# STM32F103 register map
File version: 1.0
CPU: CM3 r1p1, little endian, 4 interrupt priority bits
Registers are 32-bit, read-write, reset 0x0 unless marked. A register's access mark holds for its fields unless they carry their own. Offsets are from the block's base; [hi:lo] are bit positions; {n}, {i} and the like mark numbered series.

## CAN1 — Controller area network
Base 0x40006400
Same registers: CAN2 0x40006800
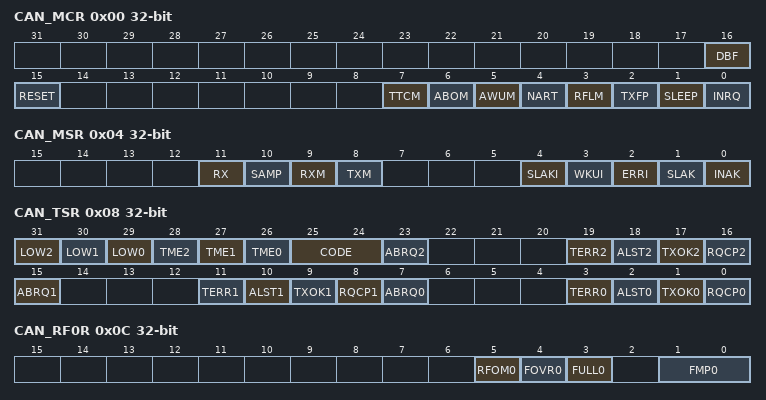
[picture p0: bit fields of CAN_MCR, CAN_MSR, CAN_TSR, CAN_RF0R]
0x00 CAN_MCR
  [16] DBF, [15] RESET, [7] TTCM, [6] ABOM, [5] AWUM, [4] NART, [3] RFLM, [2] TXFP, [1] SLEEP, [0] INRQ
0x04 CAN_MSR access per field
  [11] RX ro, [10] SAMP ro, [9] RXM ro, [8] TXM ro, [4] SLAKI rw, [3] WKUI rw, [2] ERRI rw, [1] SLAK ro, [0] INAK ro
0x08 CAN_TSR access per field
  [31] LOW2 ro — Lowest priority flag for mailbox 2
  [30] LOW1 ro — Lowest priority flag for mailbox 1
  [29] LOW0 ro — Lowest priority flag for mailbox 0
  [28] TME2 ro — Lowest priority flag for mailbox 2
  [27] TME1 ro — Lowest priority flag for mailbox 1
  [26] TME0 ro — Lowest priority flag for mailbox 0
  [25:24] CODE ro
  [23] ABRQ2 rw
  [19] TERR2 rw
  [18] ALST2 rw
  [17] TXOK2 rw
  [16] RQCP2 rw
  [15] ABRQ1 rw
  [11] TERR1 rw
  [10] ALST1 rw
  [9] TXOK1 rw
  [8] RQCP1 rw
  [7] ABRQ0 rw
  [3] TERR0 rw
  [2] ALST0 rw
  [1] TXOK0 rw
  [0] RQCP0 rw
0x0C CAN_RF0R access per field
  [5] RFOM0 rw, [4] FOVR0 rw, [3] FULL0 rw, [1:0] FMP0 ro
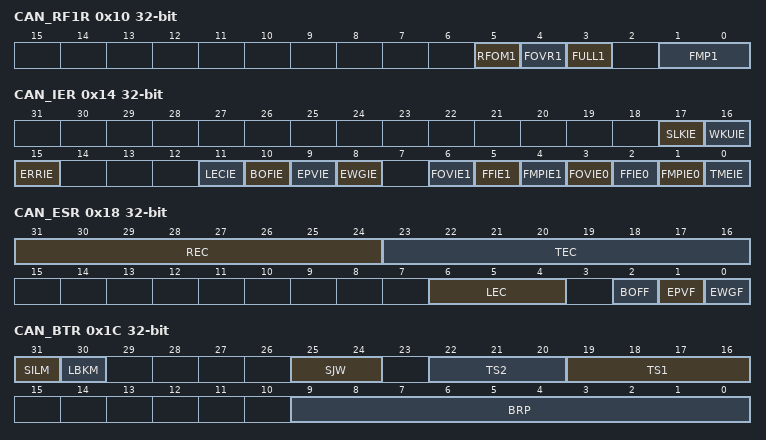
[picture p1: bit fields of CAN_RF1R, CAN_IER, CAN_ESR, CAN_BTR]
0x10 CAN_RF1R access per field
  [5] RFOM1 rw, [4] FOVR1 rw, [3] FULL1 rw, [1:0] FMP1 ro
0x14 CAN_IER
  [17] SLKIE, [16] WKUIE, [15] ERRIE, [11] LECIE, [10] BOFIE, [9] EPVIE, [8] EWGIE, [6] FOVIE1, [5] FFIE1, [4] FMPIE1, [3] FOVIE0, [2] FFIE0, [1] FMPIE0, [0] TMEIE
0x18 CAN_ESR access per field
  [31:24] REC ro, [23:16] TEC ro, [6:4] LEC rw, [2] BOFF ro, [1] EPVF ro, [0] EWGF ro
0x1C CAN_BTR
  [31] SILM, [30] LBKM, [25:24] SJW, [22:20] TS2, [19:16] TS1, [9:0] BRP
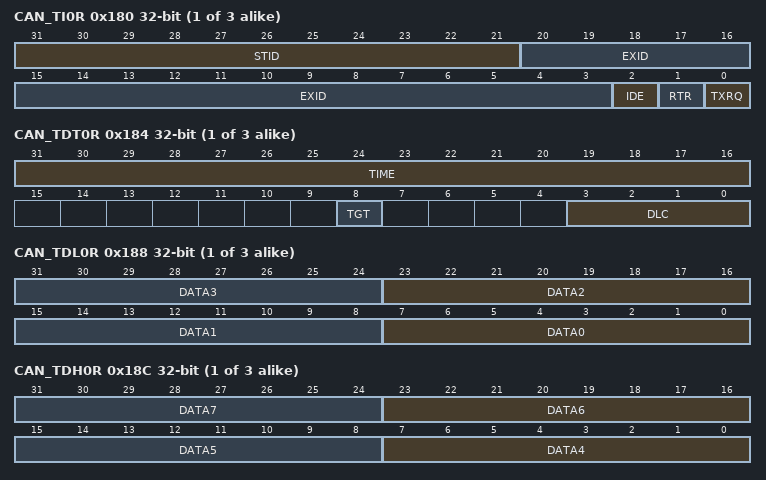
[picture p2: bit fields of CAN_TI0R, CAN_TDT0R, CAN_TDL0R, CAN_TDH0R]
{0x180+0x10*i} CAN_TI{i}R (i=0..2)
  [31:21] STID, [20:3] EXID, [2] IDE, [1] RTR, [0] TXRQ
{0x184+0x10*i} CAN_TDT{i}R (i=0..2)
  [31:16] TIME, [8] TGT, [3:0] DLC
{0x188+0x10*i} CAN_TDL{i}R (i=0..2)
  [8n+7:8n] DATA{n} (n=0..3)
{0x18C+0x10*i} CAN_TDH{i}R (i=0..2)
  [8n-25:8n-32] DATA{n} (n=4..7)
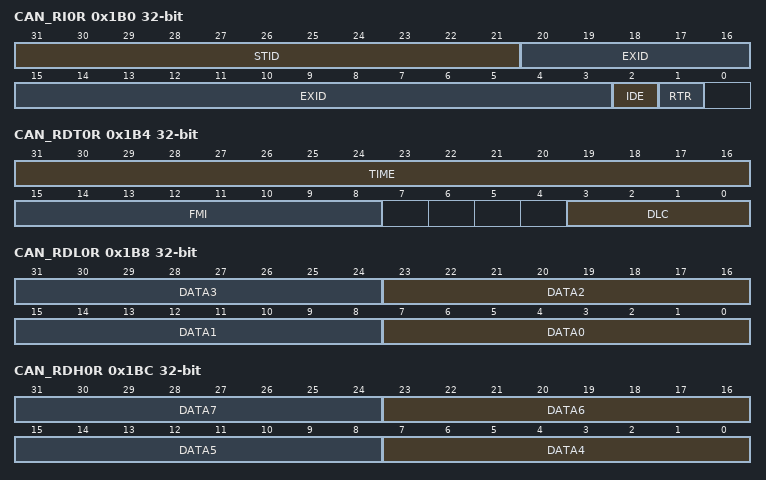
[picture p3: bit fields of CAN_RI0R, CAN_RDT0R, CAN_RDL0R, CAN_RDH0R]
0x1B0 CAN_RI0R ro
  [31:21] STID, [20:3] EXID, [2] IDE, [1] RTR
0x1B4 CAN_RDT0R ro
  [31:16] TIME, [15:8] FMI, [3:0] DLC
0x1B8 CAN_RDL0R ro
  [8n+7:8n] DATA{n} (n=0..3)
0x1BC CAN_RDH0R ro
  [8n-25:8n-32] DATA{n} (n=4..7)
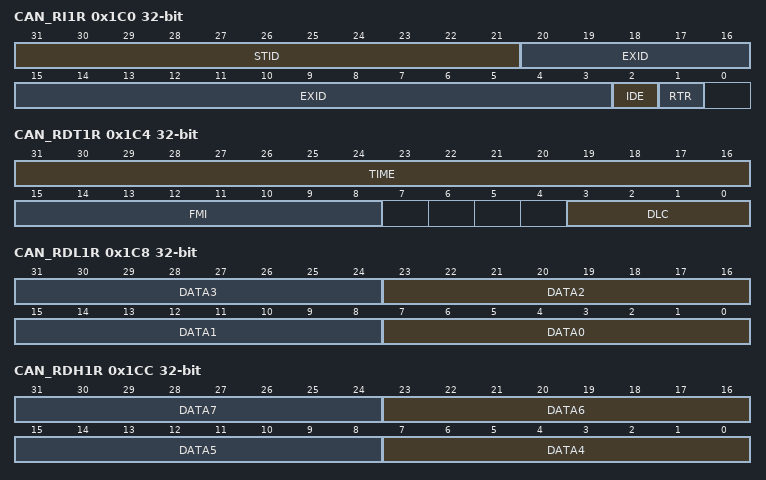
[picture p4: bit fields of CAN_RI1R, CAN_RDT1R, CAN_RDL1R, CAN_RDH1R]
0x1C0 CAN_RI1R ro
  [31:21] STID, [20:3] EXID, [2] IDE, [1] RTR
0x1C4 CAN_RDT1R ro
  [31:16] TIME, [15:8] FMI, [3:0] DLC
0x1C8 CAN_RDL1R ro
  [8n+7:8n] DATA{n} (n=0..3)
0x1CC CAN_RDH1R ro
  [8n-25:8n-32] DATA{n} (n=4..7)
0x200 CAN_FMR
  [0] FINIT
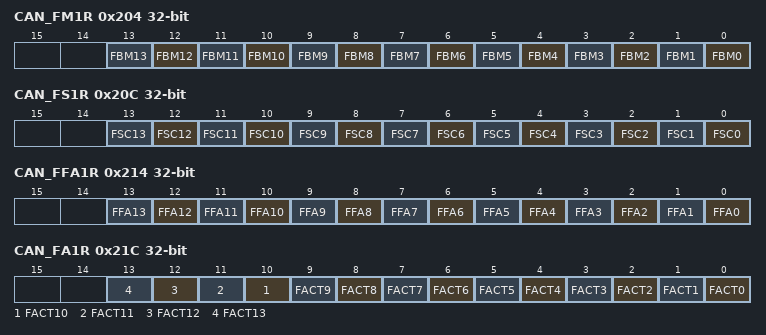
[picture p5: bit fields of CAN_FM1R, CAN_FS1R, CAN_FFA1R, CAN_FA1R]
0x204 CAN_FM1R
  [n] FBM{n} (n=0..13) — Filter mode
0x20C CAN_FS1R
  [n] FSC{n} (n=0..13) — Filter scale configuration
0x214 CAN_FFA1R
  [n] FFA{n} (n=0..13) — Filter FIFO assignment for filter {n}
0x21C CAN_FA1R
  [n] FACT{n} (n=0..13) — Filter active
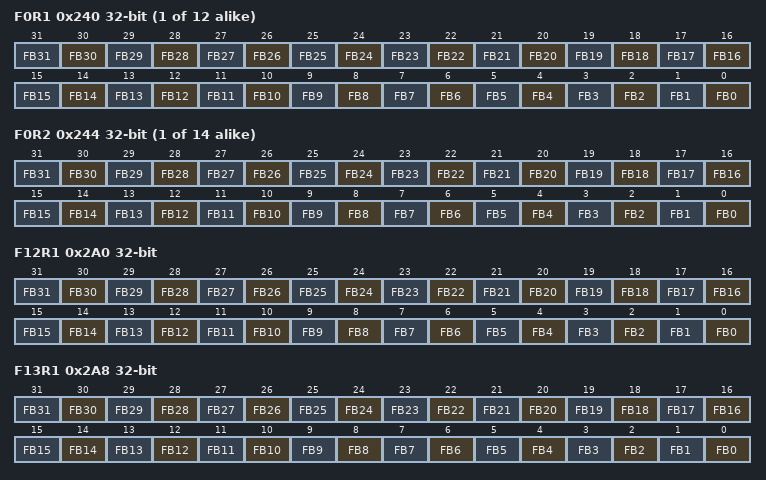
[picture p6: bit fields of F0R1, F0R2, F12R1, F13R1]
{0x240+8i} F{i}R1 (i=0..11) — Filter bank {i} register 1
  [n] FB{n} (n=0..31) — Filter bits
{0x244+8i} F{i}R2 (i=0..13) — Filter bank {i} register 2
  [n] FB{n} (n=0..31) — Filter bits
0x2A0 F12R1 — Filter bank 4 register 1
  [n] FB{n} (n=0..31) — Filter bits
0x2A8 F13R1 — Filter bank 13 register 1
  [n] FB{n} (n=0..31) — Filter bits

## DAC — Digital to analog converter
Base 0x40007400
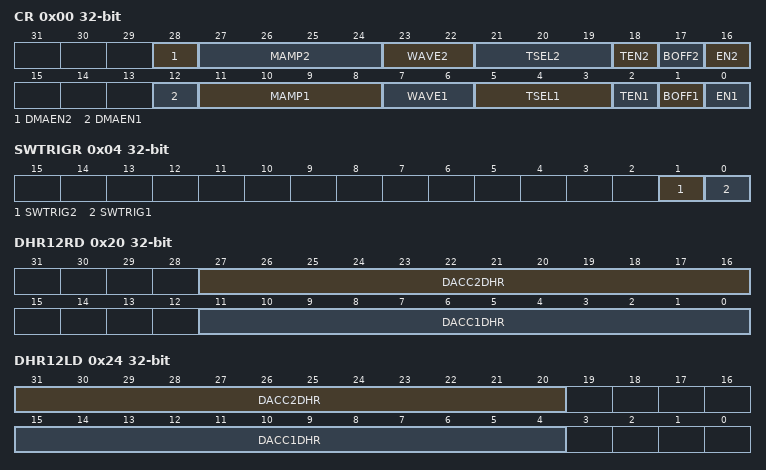
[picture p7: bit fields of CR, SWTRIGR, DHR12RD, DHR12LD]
0x00 CR — Control register (DAC_CR)
  [28] DMAEN2 — DAC channel2 DMA enable
  [27:24] MAMP2 — DAC channel2 mask/amplitude selector
  [23:22] WAVE2 — DAC channel2 noise/triangle wave generation enable
  [21:19] TSEL2 — DAC channel2 trigger selection
  [18] TEN2 — DAC channel2 trigger enable
  [17] BOFF2 — DAC channel2 output buffer disable
  [16] EN2 — DAC channel2 enable
  [12] DMAEN1 — DAC channel1 DMA enable
  [11:8] MAMP1 — DAC channel1 mask/amplitude selector
  [7:6] WAVE1 — DAC channel1 noise/triangle wave generation enable
  [5:3] TSEL1 — DAC channel1 trigger selection
  [2] TEN1 — DAC channel1 trigger enable
  [1] BOFF1 — DAC channel1 output buffer disable
  [0] EN1 — DAC channel1 enable
0x04 SWTRIGR wo — DAC software trigger register (DAC_SWTRIGR)
  [1] SWTRIG2 — DAC channel2 software trigger
  [0] SWTRIG1 — DAC channel1 software trigger
0x08 DHR12R1 — DAC channel1 12-bit right-aligned data holding register(DAC_DHR12R1)
  [11:0] DACC1DHR — DAC channel1 12-bit right-aligned data
0x0C DHR12L1 — DAC channel1 12-bit left aligned data holding register (DAC_DHR12L1)
  [15:4] DACC1DHR — DAC channel1 12-bit left-aligned data
0x10 DHR8R1 — DAC channel1 8-bit right aligned data holding register (DAC_DHR8R1)
  [7:0] DACC1DHR — DAC channel1 8-bit right-aligned data
0x14 DHR12R2 — DAC channel2 12-bit right aligned data holding register (DAC_DHR12R2)
  [11:0] DACC2DHR — DAC channel2 12-bit right-aligned data
0x18 DHR12L2 — DAC channel2 12-bit left aligned data holding register (DAC_DHR12L2)
  [15:4] DACC2DHR — DAC channel2 12-bit left-aligned data
0x1C DHR8R2 — DAC channel2 8-bit right-aligned data holding register (DAC_DHR8R2)
  [7:0] DACC2DHR — DAC channel2 8-bit right-aligned data
0x20 DHR12RD — Dual DAC 12-bit right-aligned data holding register (DAC_DHR12RD), Bits 31:28 Reserved, Bits 15:12 Reserved
  [27:16] DACC2DHR — DAC channel2 12-bit right-aligned data
  [11:0] DACC1DHR — DAC channel1 12-bit right-aligned data
0x24 DHR12LD — DUAL DAC 12-bit left aligned data holding register (DAC_DHR12LD), Bits 19:16 Reserved, Bits 3:0 Reserved
  [31:20] DACC2DHR — DAC channel2 12-bit right-aligned data
  [15:4] DACC1DHR — DAC channel1 12-bit left-aligned data
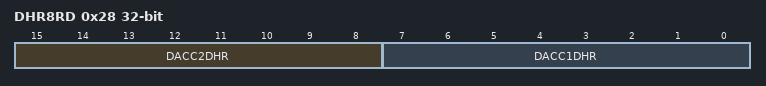
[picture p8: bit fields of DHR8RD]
0x28 DHR8RD — DUAL DAC 8-bit right aligned data holding register (DAC_DHR8RD), Bits 31:16 Reserved
  [15:8] DACC2DHR — DAC channel2 8-bit right-aligned data
  [7:0] DACC1DHR — DAC channel1 8-bit right-aligned data
0x2C DOR1 ro — DAC channel1 data output register (DAC_DOR1)
  [11:0] DACC1DOR — DAC channel1 data output
0x30 DOR2 ro — DAC channel2 data output register (DAC_DOR2)
  [11:0] DACC2DOR — DAC channel2 data output
